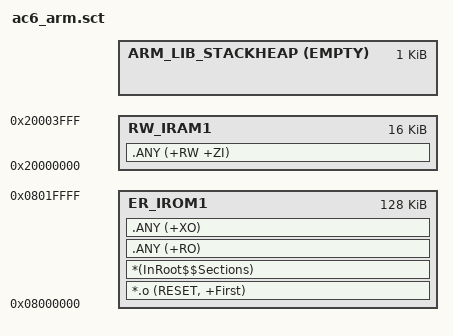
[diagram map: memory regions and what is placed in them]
#!armclang -E --target=arm-arm-none-eabi -mcpu=cortex-m7 -xc
; *************************************************************
; *** Scatter-Loading Description File generated by uVision ***
; *************************************************************
#define __STACK_SIZE    0x0000400
#define __HEAP_SIZE     0x0000400

LR_IROM1 0x08000000 0x00020000  {    ; load region size_region
    ER_IROM1 0x08000000 0x00020000  {  ; load address = execution address
        *.o (RESET, +First)
        *(InRoot$$Sections)
        .ANY (+RO)
        .ANY (+XO)
    }

    RW_IRAM1 0x20000000 0x00004000  {  ; RW data
        .ANY (+RW +ZI)
    }

    ARM_LIB_STACKHEAP +0 EMPTY 0x400 {   ; Reserve empty region for stack
    }
}
